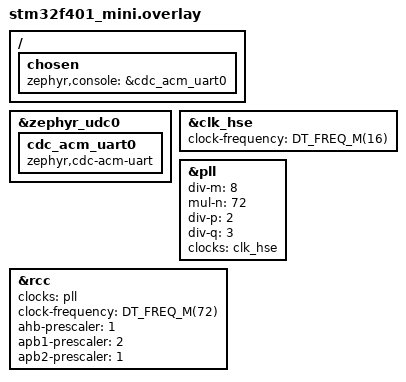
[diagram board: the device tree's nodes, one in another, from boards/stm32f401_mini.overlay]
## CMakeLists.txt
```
# SPDX-License-Identifier: Apache-2.0

cmake_minimum_required(VERSION 3.20.0)



# use base board stm32f401_mini
set(BOARD stm32f401_mini)

# use flash way openocd
set(BOARD_FLASH_RUNNER openocd)

# overlay the dts file
set(DTC_OVERLAY_FILE ${CMAKE_CURRENT_SOURCE_DIR}/boards/stm32f401_mini.overlay)

# add the dw3000-decadriver directory as a zephyr module by hand, not needed when using west
list(APPEND ZEPHYR_EXTRA_MODULES ${CMAKE_CURRENT_SOURCE_DIR}/zephyr-dw3000-driver/)

find_package(Zephyr REQUIRED HINTS $ENV{ZEPHYR_BASE})

project(zephyr-dw3000)

FILE(GLOB app_sources src/*.c)
target_sources(app PRIVATE ${app_sources})

FILE(GLOB ex_sources src/examples/*/*.c)
target_sources(app PRIVATE ${ex_sources})

FILE(GLOB share_sources src/shared_data/*.c)
target_sources(app PRIVATE ${share_sources})

target_sources(app PRIVATE src/MAC_802_15_4/mac_802_15_4.c)

target_include_directories(app PRIVATE src)
target_include_directories(app PRIVATE src/MAC_802_15_4)
target_include_directories(app PRIVATE src/shared_data)

if(TEST_READING_DEV_ID_DEF)
  message("Build example for TEST_READING_DEV_ID.")
  target_compile_definitions(app PRIVATE TEST_READING_DEV_ID)
endif()

if(TEST_AES_SS_TWR_INITIATOR_DEF)
  message("Build example for TEST_AES_SS_TWR_INITIATOR.")
  target_compile_definitions(app PRIVATE TEST_AES_SS_TWR_INITIATOR)
endif()

if(TEST_AES_SS_TWR_RESPONDER_DEF)
  message("Build example for TEST_AES_SS_TWR_RESPONDER.")
  target_compile_definitions(app PRIVATE TEST_AES_SS_TWR_RESPONDER)
endif()

target_compile_definitions(app PRIVATE CONFIG_FPU)
target_compile_definitions(app PRIVATE CMAKE_EXPORT_COMPILE_COMMANDS=1)
```

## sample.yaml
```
sample:
  name: Zephyr dw3000 application
```

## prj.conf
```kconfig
CONFIG_USB_DEVICE_STACK=y
CONFIG_USB_DEVICE_VID=0x2FE4
CONFIG_USB_DEVICE_PRODUCT="Zephyr USB console"
CONFIG_USB_DEVICE_MANUFACTURER="Vacabun"

CONFIG_SERIAL=y
CONFIG_CONSOLE=y
CONFIG_UART_CONSOLE=y
CONFIG_UART_LINE_CTRL=y

CONFIG_SPI=y
CONFIG_GPIO=y

CONFIG_DW3000=y

#使用Shell,会开启shell uart backend
CONFIG_SHELL=y

#使用log系统
CONFIG_LOG=y
CONFIG_CBPRINTF_FP_SUPPORT=y

CONFIG_MINIMAL_LIBC_MALLOC_ARENA_SIZE=1024
```

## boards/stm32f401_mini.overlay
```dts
/ {
	chosen {
		zephyr,console = &cdc_acm_uart0;
	};
};

&zephyr_udc0 {
	cdc_acm_uart0: cdc_acm_uart0 {
		compatible = "zephyr,cdc-acm-uart";
	};
};

&clk_hse {
	clock-frequency = <DT_FREQ_M(16)>;
	status = "okay";
};

&pll {
	div-m = <8>;
	mul-n = <72>;
	div-p = <2>;
	div-q = <3>;
	clocks = <&clk_hse>;
	status = "okay";
};

&rcc {
	clocks = <&pll>;
	clock-frequency = <DT_FREQ_M(72)>;
	ahb-prescaler = <1>;
	apb1-prescaler = <2>;
	apb2-prescaler = <1>;
};
```

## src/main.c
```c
/*
 * Copyright (c) 2016 Intel Corporation.
 *
 * SPDX-License-Identifier: Apache-2.0
 */

#include <zephyr/kernel.h>
#include <zephyr/sys/printk.h>
#include <zephyr/usb/usb_device.h>
#include <zephyr/drivers/uart.h>

// use swd debug
#if CONFIG_DEBUG_SWD == 1
#include "stm32f4xx_ll_system.h"
#endif

#include "dw3000.h"

BUILD_ASSERT(DT_NODE_HAS_COMPAT(DT_CHOSEN(zephyr_console), zephyr_cdc_acm_uart), "Console device is not ACM CDC UART device");
LOG_MODULE_REGISTER(main, LOG_LEVEL_DBG);

#define DEFAULT_STACKSIZE 2048

#if defined(TEST_READING_DEV_ID) || defined(TEST_AES_SS_TWR_INITIATOR) || defined(TEST_AES_SS_TWR_RESPONDER)
#define TEST_STACKSIZE 4096
#define _TEST_
#include <examples/example.h>
void (*test_fun)(void *, void *, void *);
static K_THREAD_STACK_DEFINE(test_stack, TEST_STACKSIZE);
static struct k_thread test_thread;
#endif // TEST_READING_DEV_ID TEST_AES_SS_TWR_INITIATOR TEST_AES_SS_TWR_RESPONDER

void main(void)
{
	// swd debug
#if CONFIG_DEBUG_SWD == 1
	LL_DBGMCU_EnableDBGSleepMode();
#endif

	/* usb config */
	if (usb_enable(NULL))
		return;
	k_sleep(K_MSEC(1000));

#if defined(_TEST_)
#if defined(TEST_READING_DEV_ID)
	test_fun = read_dev_id;
#endif // TEST_READING_DEV_ID

#if defined(TEST_AES_SS_TWR_INITIATOR)
	test_fun = ss_aes_twr_initiator;
#endif // TEST_AES_SS_TWR_INITIATOR

#if defined(TEST_AES_SS_TWR_RESPONDER)
	test_fun = ss_aes_twr_responder;
#endif // TEST_AES_SS_TWR_RESPONDER

	k_thread_create(&test_thread, test_stack, TEST_STACKSIZE, test_fun,
					NULL, NULL, NULL, K_PRIO_COOP(7), 0, K_NO_WAIT);
#endif //_TEST_
}
```
